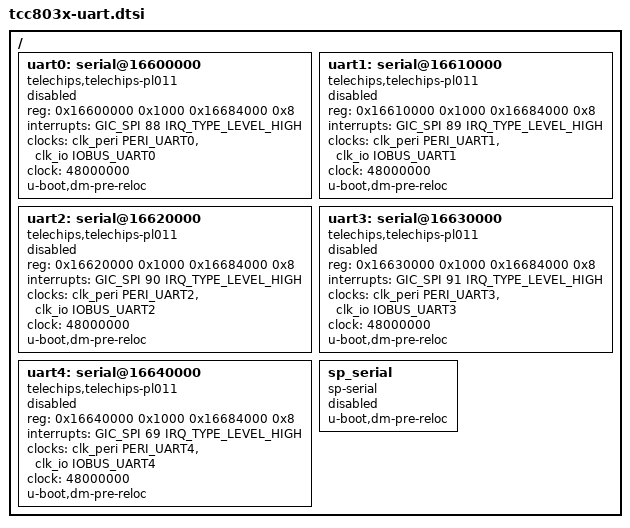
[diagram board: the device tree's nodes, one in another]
// SPDX-License-Identifier: (GPL-2.0-or-later OR MIT)
/*
 * Copyright (C) 2023 Telechips Inc.
 */

#include <dt-bindings/clock/telechips,tcc803x-clks.h>
#include <dt-bindings/interrupt-controller/arm-gic.h>

/ {
	uart0: serial@16600000 {
		compatible = "telechips,telechips-pl011", "arm,pl011", "arm,primecell";
		reg = <0x16600000 0x1000 0x16684000 0x8>;
		interrupts = <GIC_SPI 88 IRQ_TYPE_LEVEL_HIGH>;
		clocks = <&clk_peri PERI_UART0>, <&clk_io IOBUS_UART0>;
		clock = <48000000>;
		status = "disabled";
		u-boot,dm-pre-reloc;
	};

	uart1: serial@16610000 {
		compatible = "telechips,telechips-pl011", "arm,pl011", "arm,primecell";
		reg = <0x16610000 0x1000 0x16684000 0x8>;
		interrupts = <GIC_SPI 89 IRQ_TYPE_LEVEL_HIGH>;
		clocks = <&clk_peri PERI_UART1>, <&clk_io IOBUS_UART1>;
		clock = <48000000>;
		status = "disabled";
		u-boot,dm-pre-reloc;
	};

	uart2: serial@16620000 {
		compatible = "telechips,telechips-pl011", "arm,pl011", "arm,primecell";
		reg = <0x16620000 0x1000 0x16684000 0x8>;
		interrupts = <GIC_SPI 90 IRQ_TYPE_LEVEL_HIGH>;
		clocks = <&clk_peri PERI_UART2>, <&clk_io IOBUS_UART2>;
		clock = <48000000>;
		status = "disabled";
		u-boot,dm-pre-reloc;
	};

	uart3: serial@16630000 {
		compatible = "telechips,telechips-pl011", "arm,pl011", "arm,primecell";
		reg = <0x16630000 0x1000 0x16684000 0x8>;
		interrupts = <GIC_SPI 91 IRQ_TYPE_LEVEL_HIGH>;
		clocks = <&clk_peri PERI_UART3>, <&clk_io IOBUS_UART3>;
		clock = <48000000>;
		status = "disabled";
		u-boot,dm-pre-reloc;
	};

	uart4: serial@16640000 {
		compatible = "telechips,telechips-pl011", "arm,pl011", "arm,primecell";
		reg = <0x16640000 0x1000 0x16684000 0x8>;
		interrupts = <GIC_SPI 69 IRQ_TYPE_LEVEL_HIGH>;
		clocks = <&clk_peri PERI_UART4>, <&clk_io IOBUS_UART4>;
		clock = <48000000>;
		status = "disabled";
		u-boot,dm-pre-reloc;
	};

	sp_serial: sp_serial {
		compatible = "sp-serial";
		status = "disabled";
		u-boot,dm-pre-reloc;
	};
};
